# HSM_TC3xx register map
Vendor: Infineon; Series: AURIX TC3xx; File version: 2.0
CPU: CM3 r2p0, little endian, MPU, no FPU, 3 interrupt priority bits
Registers are 32-bit, read-write, no defined reset value unless marked. A register's access mark holds for its fields unless they carry their own. Offsets are from the block's base; [hi:lo] are bit positions.

## HSM_BRIDGE_HSMSIDE — HSM bridge, registers accessible by the HSM only (HSM TS 9.3.1-9.3.7). A host access gives a bus error; a debugger access through the HSM debug window reaches a host address through the HSM (possible SPB bus conflict, HSM TS 12.3.6).
Base 0xF0040000
0x24 HT2HSMIE reset 0x0 — Host to HSM Interrupt Enable
  [31:0] HT2HSMIE — Interrupt enable per HT2HSMF flag
0x40 CLKCTRL reset 0x0 — Clock Control Register
  [1:0] CLKDIV — Clock divider of the HSM subsystem
    0=DIV1 (Maximum clock frequency); 1=DIV2 (Half of the maximum clock frequency); 2=DIV4 (Quarter of the maximum clock frequency)
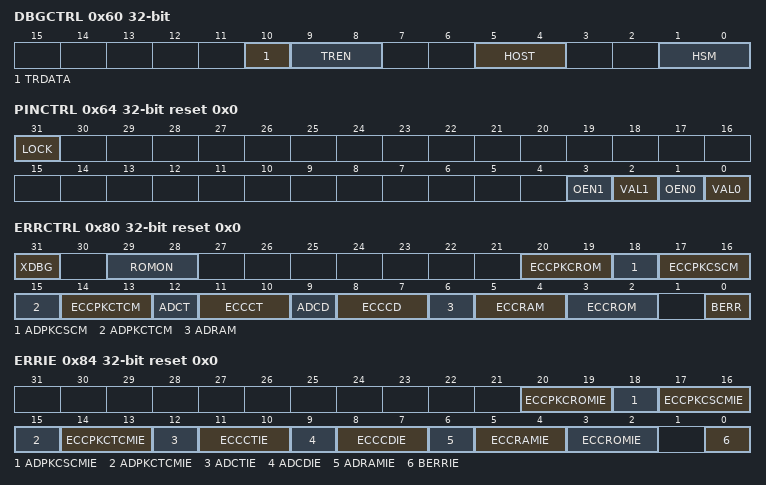
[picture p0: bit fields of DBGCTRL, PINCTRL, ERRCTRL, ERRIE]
0x60 DBGCTRL — Debug Control Register (debug and trace access of host and HSM, redundant encoding)
  [10] TRDATA — Type of trace information
    0=TRADDR (Trace addresses only); 1=TRDATA (Trace addresses and data)
  [9:8] TREN — Host side tracing of HSM accesses on SPB
    0=TRACEDIS0 (Tracing disabled); 1=TRACEDIS1 (Tracing disabled); 2=TRACEDIS2 (Tracing disabled); 3=TRACEEN (Tracing enabled)
  [5:4] HOST — Debug control for the host system
    0=HTDDIS0 (Host debug disabled); 1=HTDDIS1 (Host debug disabled); 2=HTDDIS2 (Host debug disabled); 3=HTDEN (Host debug enabled)
  [1:0] HSM — Debug control for the HSM subsystem and debug memory window
    0=HSMDDIS0 (HSM debug disabled); 1=HSMDDIS1 (HSM debug disabled); 2=HSMDDIS2 (HSM debug disabled); 3=HSMDEN (HSM debug enabled)
0x64 PINCTRL reset 0x0 — Pin Control Register (writable until LOCK is set, then read-only until reset)
  [31] LOCK
    0=UNLOCKED (Writable); 1=LOCKED (Read-only until next reset)
  [3] OEN1 — Pin 1 (HSM2) output enable
  [2] VAL1 — Pin 1 (HSM2) output value
  [1] OEN0 — Pin 0 (HSM1) output enable
  [0] VAL0 — Pin 0 (HSM1) output value
0x80 ERRCTRL reset 0x0 write-1-clears — Error Control Register (error flags, cleared by writing 1)
  [31] XDBG ro — External debugger active
  [29:28] ROMON — ROM switch (can only be cleared)
    0=ROFF (ROM switched off); 1=RON1 (ROM on); 2=RON2 (ROM on); 3=RON3 (ROM on)
  [20:19] ECCPKCROM — ECC errors of PKC ROM (1: correctable, 2: uncorrectable, 3: both)
  [18] ADPKCSCM — Address error of PKC SCM
  [17:16] ECCPKCSCM — ECC errors of PKC SCM (1: correctable, 2: uncorrectable, 3: both)
  [15] ADPKCTCM — Address error of PKC TCM
  [14:13] ECCPKCTCM — ECC errors of PKC TCM (1: correctable, 2: uncorrectable, 3: both)
  [12] ADCT — Address error of cache tag field
  [11:10] ECCCT — ECC errors of cache tag field (1: correctable, 2: uncorrectable, 3: both)
  [9] ADCD — Address error of cache data
  [8:7] ECCCD — ECC errors of cache data (1: correctable, 2: uncorrectable, 3: both)
  [6] ADRAM — Address error of local RAM
  [5:4] ECCRAM — ECC errors of local RAM (1: correctable, 2: uncorrectable, 3: both)
  [3:2] ECCROM — ECC errors of HSM boot ROM (1: correctable, 2: uncorrectable, 3: both)
  [0] BERR — Host system bus error due to an HSM access
0x84 ERRIE reset 0x0 — Error Interrupt Enable Register
  [20:19] ECCPKCROMIE — PKC ROM ECC error interrupt enable (1: correctable, 2: uncorrectable, 3: both)
  [18] ADPKCSCMIE — PKC SCM address error interrupt enable
  [17:16] ECCPKCSCMIE — PKC SCM ECC error interrupt enable
  [15] ADPKCTCMIE — PKC TCM address error interrupt enable
  [14:13] ECCPKCTCMIE — PKC TCM ECC error interrupt enable
  [12] ADCTIE — Cache tag address error interrupt enable
  [11:10] ECCCTIE — Cache tag ECC error interrupt enable
  [9] ADCDIE — Cache data address error interrupt enable
  [8:7] ECCCDIE — Cache data ECC error interrupt enable
  [6] ADRAMIE — Local RAM address error interrupt enable
  [5:4] ECCRAMIE — Local RAM ECC error interrupt enable
  [3:2] ECCROMIE — Boot ROM ECC error interrupt enable
  [0] BERRIE — Bus error interrupt enable
0x88 ERRADDR ro reset 0x0 — Error Address Register (address of the last bus error)
  [31:0] ADDR — Error address
0xA0 EXTIF reset 0x0 write-1-clears — External Interrupt Flag Register
  [31:0] EXTIF — External interrupt flags
0xA4 EXTIE reset 0x0 — External Interrupt Enable
  [31:0] EXTIE — Interrupt enable per EXTIF flag
0xC0 SAHBASE reset 0xF0000000 — Single Access to Host Base Address Register
  [31:16] BASE — Base address of the single access to host window (Fxxx: window off)
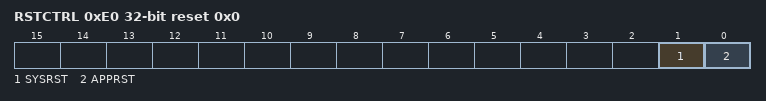
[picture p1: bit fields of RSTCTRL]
0xE0 RSTCTRL reset 0x0 — Reset Control Register (writable only while RSTPWD holds 55AA00FFH)
  [1] SYSRST — Trigger a system reset
  [0] APPRST — Trigger an application reset
0xE4 RSTPWD wo reset 0x0 — Reset Password Register
  [31:0] PASSWD — 55AA00FFH makes RSTCTRL writable
0xF0 SENSIF reset 0x0 write-1-clears — Sensor Interrupt Flag Register
  [9:0] SENSIF — Sensor flags
0xF4 SENSIE reset 0x0 — Sensor Interrupt Enable Register
  [9:0] SENSIE — Sensor interrupt enable
0xF8 SENSAPPRST reset 0x0 — Sensor Application Reset Enable Register
  [9:0] AREN — Application reset enable per sensor flag
0xFC SENSSYSRST reset 0x0 — Sensor System Reset Enable Register
  [9:0] SREN — System reset enable per sensor flag
